# AT90USB1287 register map
Vendor: Atmel; File version: 1.0
CPU: other r0p0, little endian, no MPU, no FPU, 4 interrupt priority bits
Registers are 8-bit, read-write, reset 0x0 unless marked. A register's access mark holds for its fields unless they carry their own. Offsets are from the block's base; lines under a group give offsets from that group; [hi:lo] are bit positions; {n}, {i} and the like mark numbered series; 'fields as' and 'values as' point back to an identical list; <NAME> marks a mode.

## Memory map
0x00000000 FUSE size 0x3 — Fuses
0x00000000 LOCKBIT size 0x1 — Lockbits
0x00000020 PORTA size 0x3 — I/O Port
0x00000023 PORTB size 0x3 — I/O Port
0x00000026 PORTC size 0x3 — I/O Port
0x00000029 PORTD size 0x3 — I/O Port
0x0000002C PORTE size 0x3 — I/O Port
0x0000002F PORTF size 0x3 — I/O Port
0x00000035 TC0 blocks up to offset 0x3A — Timer/Counter, 8-bit
0x00000036 TC1 blocks up to offset 0x58 — Timer/Counter, 16-bit
0x00000037 TC2 blocks up to offset 0x80 — Timer/Counter, 8-bit Async
0x00000038 TC3 blocks up to offset 0x66 — Timer/Counter, 16-bit
0x0000003B EXINT blocks up to offset 0x31 — External Interrupts
0x0000003E CPU blocks up to offset 0x38 — CPU Registers
0x0000003F EEPROM size 0x4
0x00000049 PLL size 0x1 — Phase Locked Loop
0x0000004C SPI size 0x3 — Serial Peripheral Interface
0x00000050 AC blocks up to offset 0x30 — Analog Comparator
0x00000051 JTAG blocks up to offset 0x5 — JTAG Interface
0x00000057 BOOT_LOAD size 0x1 — Bootloader
0x00000060 WDT size 0x1 — Watchdog Timer
0x00000078 ADC blocks up to offset 0x7 — Analog-to-Digital Converter
0x0000009E USB_HOST blocks up to offset 0x5B — USB Host Registers
0x000000B8 TWI size 0x6 — Two Wire Serial Interface
0x000000C8 USART1 blocks up to offset 0x7 — USART
0x000000D7 USB_GLOBAL blocks up to offset 0x23 — USB Controller
0x000000E0 USB_DEVICE blocks up to offset 0x15 — USB Device Registers

## Interrupts
0 RESET (CPU) — External Pin,Power-on Reset,Brown-out Reset,Watchdog Reset,and JTAG AVR Reset. See Datasheet.
{n+1} INT{n} (CPU) (n=0..7) — External Interrupt Request {n}
9 PCINT0 (CPU) — Pin Change Interrupt Request 0
10 USB_GEN (CPU) — USB General Interrupt Request
11 USB_COM (CPU) — USB Endpoint/Pipe Interrupt Communication Request
12 WDT (CPU) — Watchdog Time-out Interrupt
13 TIMER2_COMPA (CPU) — Timer/Counter2 Compare Match A
14 TIMER2_COMPB (CPU) — Timer/Counter2 Compare Match B
15 TIMER2_OVF (CPU) — Timer/Counter2 Overflow
16 TIMER1_CAPT (CPU) — Timer/Counter1 Capture Event
17 TIMER1_COMPA (CPU) — Timer/Counter1 Compare Match A
18 TIMER1_COMPB (CPU) — Timer/Counter1 Compare Match B
19 TIMER1_COMPC (CPU) — Timer/Counter1 Compare Match C
20 TIMER1_OVF (CPU) — Timer/Counter1 Overflow
21 TIMER0_COMPA (CPU) — Timer/Counter0 Compare Match A
22 TIMER0_COMPB (CPU) — Timer/Counter0 Compare Match B
23 TIMER0_OVF (CPU) — Timer/Counter0 Overflow
24 SPI_STC (CPU) — SPI Serial Transfer Complete
25 USART1_RX (CPU) — USART1, Rx Complete
26 USART1_UDRE (CPU) — USART1 Data register Empty
27 USART1_TX (CPU) — USART1, Tx Complete
28 ANALOG_COMP (CPU) — Analog Comparator
29 ADC (CPU) — ADC Conversion Complete
30 EE_READY (CPU) — EEPROM Ready
31 TIMER3_CAPT (CPU) — Timer/Counter3 Capture Event
32 TIMER3_COMPA (CPU) — Timer/Counter3 Compare Match A
33 TIMER3_COMPB (CPU) — Timer/Counter3 Compare Match B
34 TIMER3_COMPC (CPU) — Timer/Counter3 Compare Match C
35 TIMER3_OVF (CPU) — Timer/Counter3 Overflow
36 TWI (CPU) — 2-wire Serial Interface
37 SPM_READY (CPU) — Store Program Memory Read

## AC — Analog Comparator
Base 0x00000050
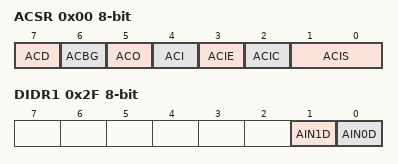
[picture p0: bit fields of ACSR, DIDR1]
0x00 ACSR — Analog Comparator Control And Status Register
  [7] ACD — Analog Comparator Disable
  [6] ACBG — Analog Comparator Bandgap Select
  [5] ACO — Analog Compare Output
  [4] ACI — Analog Comparator Interrupt Flag
  [3] ACIE — Analog Comparator Interrupt Enable
  [2] ACIC — Analog Comparator Input Capture Enable
  [1:0] ACIS — Analog Comparator Interrupt Mode Select bits
    0=INTERRUPT_ON_TOGGLE; 2=INTERRUPT_ON_FALLING_EDGE; 3=INTERRUPT_ON_RISING_EDGE
0x2B ADCSRB — ADC Control and Status Register B
  [6] ACME — Analog Comparator Multiplexer Enable
0x2F DIDR1
  [1] AIN1D — AIN1 Digital Input Disable
  [0] AIN0D — AIN0 Digital Input Disable
